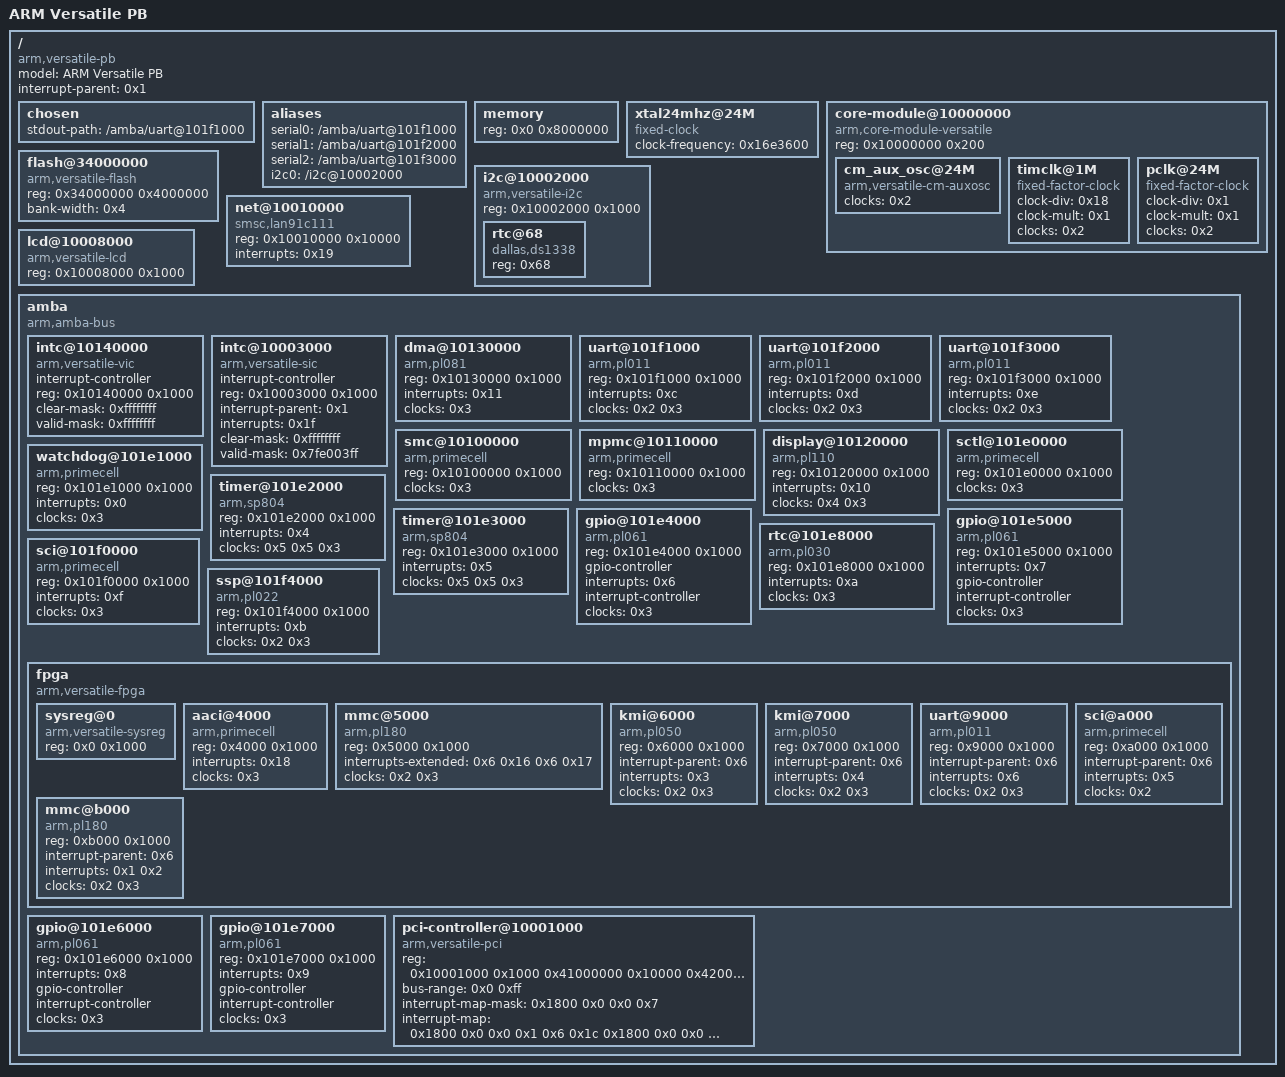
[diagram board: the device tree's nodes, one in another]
/dts-v1/;

/ {
	#address-cells = <0x1>;
	#size-cells = <0x1>;
	model = "ARM Versatile PB";
	compatible = "arm,versatile-pb";
	interrupt-parent = <0x1>;

	chosen {
		stdout-path = "/amba/uart@101f1000";
	};

	aliases {
		serial0 = "/amba/uart@101f1000";
		serial1 = "/amba/uart@101f2000";
		serial2 = "/amba/uart@101f3000";
		i2c0 = "/i2c@10002000";
	};

	memory {
		device_type = "memory";
		reg = <0x0 0x8000000>;
	};

	xtal24mhz@24M {
		#clock-cells = <0x0>;
		compatible = "fixed-clock";
		clock-frequency = <0x16e3600>;
		phandle = <0x2>;
	};

	core-module@10000000 {
		compatible = "arm,core-module-versatile", "syscon";
		reg = <0x10000000 0x200>;

		cm_aux_osc@24M {
			#clock-cells = <0x0>;
			compatible = "arm,versatile-cm-auxosc";
			clocks = <0x2>;
			phandle = <0x4>;
		};

		timclk@1M {
			#clock-cells = <0x0>;
			compatible = "fixed-factor-clock";
			clock-div = <0x18>;
			clock-mult = <0x1>;
			clocks = <0x2>;
			phandle = <0x5>;
		};

		pclk@24M {
			#clock-cells = <0x0>;
			compatible = "fixed-factor-clock";
			clock-div = <0x1>;
			clock-mult = <0x1>;
			clocks = <0x2>;
			phandle = <0x3>;
		};
	};

	flash@34000000 {
		compatible = "arm,versatile-flash";
		reg = <0x34000000 0x4000000>;
		bank-width = <0x4>;
	};

	i2c@10002000 {
		#address-cells = <0x1>;
		#size-cells = <0x0>;
		compatible = "arm,versatile-i2c";
		reg = <0x10002000 0x1000>;

		rtc@68 {
			compatible = "dallas,ds1338";
			reg = <0x68>;
		};
	};

	net@10010000 {
		compatible = "smsc,lan91c111";
		reg = <0x10010000 0x10000>;
		interrupts = <0x19>;
	};

	lcd@10008000 {
		compatible = "arm,versatile-lcd";
		reg = <0x10008000 0x1000>;
	};

	amba {
		compatible = "arm,amba-bus";
		#address-cells = <0x1>;
		#size-cells = <0x1>;
		ranges;

		intc@10140000 {
			compatible = "arm,versatile-vic";
			interrupt-controller;
			#interrupt-cells = <0x1>;
			reg = <0x10140000 0x1000>;
			clear-mask = <0xffffffff>;
			valid-mask = <0xffffffff>;
			phandle = <0x1>;
		};

		intc@10003000 {
			compatible = "arm,versatile-sic";
			interrupt-controller;
			#interrupt-cells = <0x1>;
			reg = <0x10003000 0x1000>;
			interrupt-parent = <0x1>;
			interrupts = <0x1f>;
			clear-mask = <0xffffffff>;
			valid-mask = <0x7fe003ff>;
			phandle = <0x6>;
		};

		dma@10130000 {
			compatible = "arm,pl081", "arm,primecell";
			reg = <0x10130000 0x1000>;
			interrupts = <0x11>;
			clocks = <0x3>;
			clock-names = "apb_pclk";
		};

		uart@101f1000 {
			compatible = "arm,pl011", "arm,primecell";
			reg = <0x101f1000 0x1000>;
			interrupts = <0xc>;
			clocks = <0x2 0x3>;
			clock-names = "uartclk", "apb_pclk";
		};

		uart@101f2000 {
			compatible = "arm,pl011", "arm,primecell";
			reg = <0x101f2000 0x1000>;
			interrupts = <0xd>;
			clocks = <0x2 0x3>;
			clock-names = "uartclk", "apb_pclk";
		};

		uart@101f3000 {
			compatible = "arm,pl011", "arm,primecell";
			reg = <0x101f3000 0x1000>;
			interrupts = <0xe>;
			clocks = <0x2 0x3>;
			clock-names = "uartclk", "apb_pclk";
		};

		smc@10100000 {
			compatible = "arm,primecell";
			reg = <0x10100000 0x1000>;
			clocks = <0x3>;
			clock-names = "apb_pclk";
		};

		mpmc@10110000 {
			compatible = "arm,primecell";
			reg = <0x10110000 0x1000>;
			clocks = <0x3>;
			clock-names = "apb_pclk";
		};

		display@10120000 {
			compatible = "arm,pl110", "arm,primecell";
			reg = <0x10120000 0x1000>;
			interrupts = <0x10>;
			clocks = <0x4 0x3>;
			clock-names = "clcd", "apb_pclk";
		};

		sctl@101e0000 {
			compatible = "arm,primecell";
			reg = <0x101e0000 0x1000>;
			clocks = <0x3>;
			clock-names = "apb_pclk";
		};

		watchdog@101e1000 {
			compatible = "arm,primecell";
			reg = <0x101e1000 0x1000>;
			interrupts = <0x0>;
			clocks = <0x3>;
			clock-names = "apb_pclk";
		};

		timer@101e2000 {
			compatible = "arm,sp804", "arm,primecell";
			reg = <0x101e2000 0x1000>;
			interrupts = <0x4>;
			clocks = <0x5 0x5 0x3>;
			clock-names = "timer0", "timer1", "apb_pclk";
		};

		timer@101e3000 {
			compatible = "arm,sp804", "arm,primecell";
			reg = <0x101e3000 0x1000>;
			interrupts = <0x5>;
			clocks = <0x5 0x5 0x3>;
			clock-names = "timer0", "timer1", "apb_pclk";
		};

		gpio@101e4000 {
			compatible = "arm,pl061", "arm,primecell";
			reg = <0x101e4000 0x1000>;
			gpio-controller;
			interrupts = <0x6>;
			#gpio-cells = <0x2>;
			interrupt-controller;
			#interrupt-cells = <0x2>;
			clocks = <0x3>;
			clock-names = "apb_pclk";
		};

		gpio@101e5000 {
			compatible = "arm,pl061", "arm,primecell";
			reg = <0x101e5000 0x1000>;
			interrupts = <0x7>;
			gpio-controller;
			#gpio-cells = <0x2>;
			interrupt-controller;
			#interrupt-cells = <0x2>;
			clocks = <0x3>;
			clock-names = "apb_pclk";
		};

		rtc@101e8000 {
			compatible = "arm,pl030", "arm,primecell";
			reg = <0x101e8000 0x1000>;
			interrupts = <0xa>;
			clocks = <0x3>;
			clock-names = "apb_pclk";
		};

		sci@101f0000 {
			compatible = "arm,primecell";
			reg = <0x101f0000 0x1000>;
			interrupts = <0xf>;
			clocks = <0x3>;
			clock-names = "apb_pclk";
		};

		ssp@101f4000 {
			compatible = "arm,pl022", "arm,primecell";
			reg = <0x101f4000 0x1000>;
			interrupts = <0xb>;
			clocks = <0x2 0x3>;
			clock-names = "SSPCLK", "apb_pclk";
		};

		fpga {
			compatible = "arm,versatile-fpga", "simple-bus";
			#address-cells = <0x1>;
			#size-cells = <0x1>;
			ranges = <0x0 0x10000000 0x10000>;

			sysreg@0 {
				compatible = "arm,versatile-sysreg", "syscon";
				reg = <0x0 0x1000>;
			};

			aaci@4000 {
				compatible = "arm,primecell";
				reg = <0x4000 0x1000>;
				interrupts = <0x18>;
				clocks = <0x3>;
				clock-names = "apb_pclk";
			};

			mmc@5000 {
				compatible = "arm,pl180", "arm,primecell";
				reg = <0x5000 0x1000>;
				interrupts-extended = <0x6 0x16 0x6 0x17>;
				clocks = <0x2 0x3>;
				clock-names = "mclk", "apb_pclk";
			};

			kmi@6000 {
				compatible = "arm,pl050", "arm,primecell";
				reg = <0x6000 0x1000>;
				interrupt-parent = <0x6>;
				interrupts = <0x3>;
				clocks = <0x2 0x3>;
				clock-names = "KMIREFCLK", "apb_pclk";
			};

			kmi@7000 {
				compatible = "arm,pl050", "arm,primecell";
				reg = <0x7000 0x1000>;
				interrupt-parent = <0x6>;
				interrupts = <0x4>;
				clocks = <0x2 0x3>;
				clock-names = "KMIREFCLK", "apb_pclk";
			};

			uart@9000 {
				compatible = "arm,pl011", "arm,primecell";
				reg = <0x9000 0x1000>;
				interrupt-parent = <0x6>;
				interrupts = <0x6>;
				clocks = <0x2 0x3>;
				clock-names = "uartclk", "apb_pclk";
			};

			sci@a000 {
				compatible = "arm,primecell";
				reg = <0xa000 0x1000>;
				interrupt-parent = <0x6>;
				interrupts = <0x5>;
				clocks = <0x2>;
				clock-names = "apb_pclk";
			};

			mmc@b000 {
				compatible = "arm,pl180", "arm,primecell";
				reg = <0xb000 0x1000>;
				interrupt-parent = <0x6>;
				interrupts = <0x1 0x2>;
				clocks = <0x2 0x3>;
				clock-names = "mclk", "apb_pclk";
			};
		};

		gpio@101e6000 {
			compatible = "arm,pl061", "arm,primecell";
			reg = <0x101e6000 0x1000>;
			interrupts = <0x8>;
			gpio-controller;
			#gpio-cells = <0x2>;
			interrupt-controller;
			#interrupt-cells = <0x2>;
			clocks = <0x3>;
			clock-names = "apb_pclk";
		};

		gpio@101e7000 {
			compatible = "arm,pl061", "arm,primecell";
			reg = <0x101e7000 0x1000>;
			interrupts = <0x9>;
			gpio-controller;
			#gpio-cells = <0x2>;
			interrupt-controller;
			#interrupt-cells = <0x2>;
			clocks = <0x3>;
			clock-names = "apb_pclk";
		};

		pci-controller@10001000 {
			compatible = "arm,versatile-pci";
			device_type = "pci";
			reg = <0x10001000 0x1000 0x41000000 0x10000 0x42000000 0x100000>;
			bus-range = <0x0 0xff>;
			#address-cells = <0x3>;
			#size-cells = <0x2>;
			#interrupt-cells = <0x1>;
			ranges = <0x1000000 0x0 0x0 0x43000000 0x0 0x10000 0x2000000 0x0 0x50000000 0x50000000 0x0 0x10000000 0x42000000 0x0 0x60000000 0x60000000 0x0 0x10000000>;
			interrupt-map-mask = <0x1800 0x0 0x0 0x7>;
			interrupt-map = <0x1800 0x0 0x0 0x1 0x6 0x1c 0x1800 0x0 0x0 0x2 0x6 0x1d 0x1800 0x0 0x0 0x3 0x6 0x1e 0x1800 0x0 0x0 0x4 0x6 0x1b 0x1000 0x0 0x0 0x1 0x6 0x1b 0x1000 0x0 0x0 0x2 0x6 0x1c 0x1000 0x0 0x0 0x3 0x6 0x1d 0x1000 0x0 0x0 0x4 0x6 0x1e 0x800 0x0 0x0 0x1 0x6 0x1e 0x800 0x0 0x0 0x2 0x6 0x1b 0x800 0x0 0x0 0x3 0x6 0x1c 0x800 0x0 0x0 0x4 0x6 0x1d 0x0 0x0 0x0 0x1 0x6 0x1d 0x0 0x0 0x0 0x2 0x6 0x1e 0x0 0x0 0x0 0x3 0x6 0x1b 0x0 0x0 0x0 0x4 0x6 0x1c>;
		};
	};
};
